# MSPM0G350X register map
Vendor: Texas Instruments; File version: This preliminary header file does not have a version number - build date: 2023-02-21 16:25:48
CPU: CM0 r0p1, little endian, MPU, no FPU, 3 interrupt priority bits
Registers are 32-bit, read-write, reset 0x0 unless marked. A register's access mark holds for its fields unless they carry their own. Offsets are from the block's base; [hi:lo] are bit positions; {n}, {i} and the like mark numbered series.

## COMP0 — PERIPHERALREGION
Base 0x40008000
Same registers: COMP1 0x4000A000, COMP2 0x4000C000
0x400 FSUB_0 — Subscriber Port 0
  [3:0] FSUB_0_CHANID — 0 = disconnected. 1-15 = connected to channelID = CHANID.
    0=FSUB_0_CHANID_UNCONNECTED (UNCONNECTED)
0x404 FSUB_1 — Subscriber Port 1
  [3:0] FSUB_1_CHANID — 0 = disconnected. 1-15 = connected to channelID = CHANID.
    0=FSUB_1_CHANID_UNCONNECTED (UNCONNECTED)
0x444 FPUB_1 — Publisher port 1
  [3:0] FPUB_1_CHANID — 0 = disconnected. 1-15 = connected to channelID = CHANID.
    0=FPUB_1_CHANID_UNCONNECTED (UNCONNECTED)
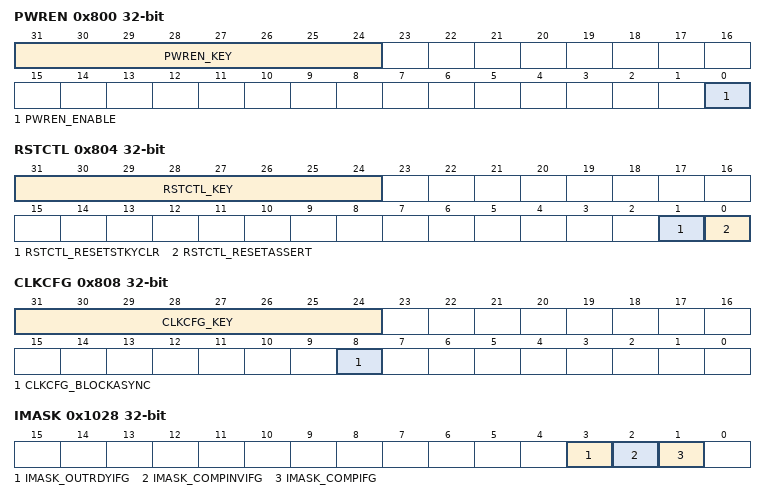
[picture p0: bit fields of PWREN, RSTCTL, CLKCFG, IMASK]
0x800 PWREN — Power enable
  [31:24] PWREN_KEY wo — KEY to allow Power State Change
    38=PWREN_KEY_UNLOCK_W (_TO_UNLOCK_W_)
  [0] PWREN_ENABLE — Enable the power
    0=PWREN_ENABLE_DISABLE (DISABLE); 1=PWREN_ENABLE_ENABLE (ENABLE)
0x804 RSTCTL wo — Reset Control
  [31:24] RSTCTL_KEY — Unlock key
    177=RSTCTL_KEY_UNLOCK_W (_TO_UNLOCK_W_)
  [1] RSTCTL_RESETSTKYCLR — Clear the RESETSTKY bit in the STAT register
    0=RSTCTL_RESETSTKYCLR_NOP (NOP); 1=RSTCTL_RESETSTKYCLR_CLR (CLR)
  [0] RSTCTL_RESETASSERT — Assert reset to the peripheral
    0=RSTCTL_RESETASSERT_NOP (NOP); 1=RSTCTL_RESETASSERT_ASSERT (ASSERT)
0x808 CLKCFG — Peripheral Clock Configuration Register
  [31:24] CLKCFG_KEY wo — KEY to Allow State Change -- 0xA9
    169=CLKCFG_KEY_UNLOCK (_UNLOCK_W_)
  [8] CLKCFG_BLOCKASYNC — Async Clock Request is blocked from starting SYSOSC or forcing bus clock to 32MHz
    0=CLKCFG_BLOCKASYNC_DISABLE (DISABLE); 1=CLKCFG_BLOCKASYNC_ENABLE (ENABLE)
0x814 GPRCM_STAT ro — Status Register
  [16] GPRCM_STAT_RESETSTKY — This bit indicates, if the peripheral was reset, since this bit was cleared by RESETSTKYCLR in the RSTCTL register
    0=GPRCM_STAT_RESETSTKY_NORES (NORES); 1=GPRCM_STAT_RESETSTKY_RESET (RESET)
0x1020 IIDX ro — Interrupt index
  [1:0] IIDX_STAT — Interrupt index status
    0=IIDX_STAT_NO_INTR (NO_INTR); 1=IIDX_STAT_OUTRDYIFG (OUTRDYIFG); 2=IIDX_STAT_COMPIFG (COMPIFG); 3=IIDX_STAT_COMPINVIFG (COMPINVIFG)
0x1028 IMASK — Interrupt mask
  [3] IMASK_OUTRDYIFG — Masks OUTRDYIFG
    0=IMASK_OUTRDYIFG_CLR (CLR); 1=IMASK_OUTRDYIFG_SET (SET)
  [2] IMASK_COMPINVIFG — Masks COMPINVIFG
    0=IMASK_COMPINVIFG_CLR (CLR); 1=IMASK_COMPINVIFG_SET (SET)
  [1] IMASK_COMPIFG — Masks COMPIFG
    0=IMASK_COMPIFG_CLR (CLR); 1=IMASK_COMPIFG_SET (SET)
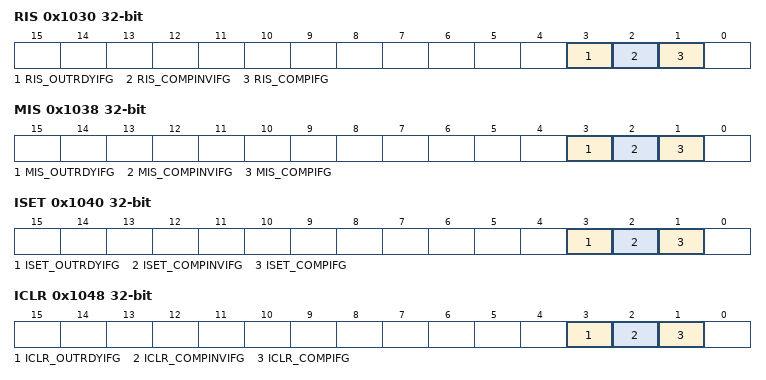
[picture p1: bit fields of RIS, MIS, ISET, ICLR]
0x1030 RIS ro — Raw interrupt status
  [3] RIS_OUTRDYIFG — Raw interrupt status for comparator output ready interrupt flag. This bit is set when the comparator output is valid.
    0=RIS_OUTRDYIFG_CLR (CLR); 1=RIS_OUTRDYIFG_SET (SET)
  [2] RIS_COMPINVIFG — Raw interrupt status for comparator output inverted interrupt flag. The IES bit defines the transition of the comparator output setting this bit.
    0=RIS_COMPINVIFG_CLR (CLR); 1=RIS_COMPINVIFG_SET (SET)
  [1] RIS_COMPIFG — Raw interrupt status for comparator output interrupt flag. The IES bit defines the transition of the comparator output setting this bit.
    0=RIS_COMPIFG_CLR (CLR); 1=RIS_COMPIFG_SET (SET)
0x1038 MIS ro — Masked interrupt status
  [3] MIS_OUTRDYIFG — Masked interrupt status for OUTRDYIFG
    0=MIS_OUTRDYIFG_CLR (CLR); 1=MIS_OUTRDYIFG_SET (SET)
  [2] MIS_COMPINVIFG — Masked interrupt status for COMPINVIFG
    0=MIS_COMPINVIFG_CLR (CLR); 1=MIS_COMPINVIFG_SET (SET)
  [1] MIS_COMPIFG — Masked interrupt status for COMPIFG
    0=MIS_COMPIFG_CLR (CLR); 1=MIS_COMPIFG_SET (SET)
0x1040 ISET wo — Interrupt set
  [3] ISET_OUTRDYIFG — Sets OUTRDYIFG in RIS register
    0=ISET_OUTRDYIFG_NO_EFFECT (NO_EFFECT); 1=ISET_OUTRDYIFG_SET (SET)
  [2] ISET_COMPINVIFG — Sets COMPINVIFG in RIS register
    0=ISET_COMPINVIFG_NO_EFFECT (NO_EFFECT); 1=ISET_COMPINVIFG_SET (SET)
  [1] ISET_COMPIFG — Sets COMPIFG in RIS register
    0=ISET_COMPIFG_NO_EFFECT (NO_EFFECT); 1=ISET_COMPIFG_SET (SET)
0x1048 ICLR wo — Interrupt clear
  [3] ICLR_OUTRDYIFG — Clears OUTRDYIFG in RIS register
    0=ICLR_OUTRDYIFG_NO_EFFECT (NO_EFFECT); 1=ICLR_OUTRDYIFG_CLR (CLR)
  [2] ICLR_COMPINVIFG — Clears COMPINVIFG in RIS register
    0=ICLR_COMPINVIFG_NO_EFFECT (NO_EFFECT); 1=ICLR_COMPINVIFG_CLR (CLR)
  [1] ICLR_COMPIFG — Clears COMPIFG in RIS register
    0=ICLR_COMPIFG_NO_EFFECT (NO_EFFECT); 1=ICLR_COMPIFG_CLR (CLR)
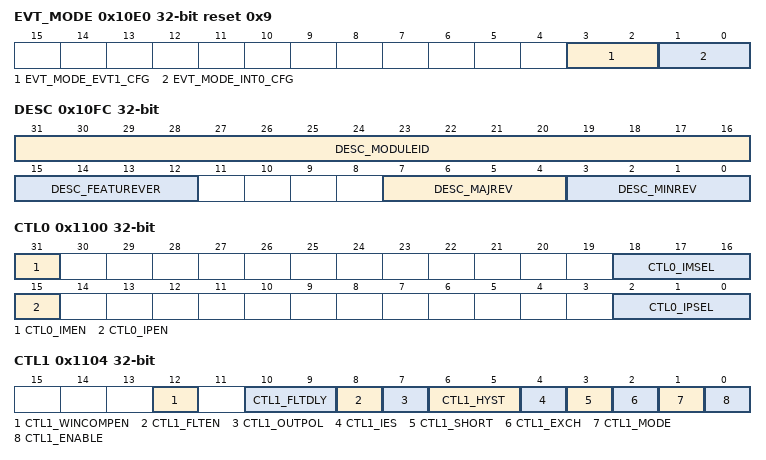
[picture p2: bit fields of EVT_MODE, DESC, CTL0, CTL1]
0x10E0 EVT_MODE reset 0x9 — Event Mode
  [3:2] EVT_MODE_EVT1_CFG ro — Event line mode select for event corresponding to [IPSTANDARD.INT_EVENT][0]
    0=EVT_MODE_EVT1_CFG_DISABLE (DISABLE); 1=EVT_MODE_EVT1_CFG_SOFTWARE (SOFTWARE); 2=EVT_MODE_EVT1_CFG_HARDWARE (HARDWARE)
  [1:0] EVT_MODE_INT0_CFG ro — Event line mode select for event corresponding to [IPSTANDARD.INT_EVENT][0]
    0=EVT_MODE_INT0_CFG_DISABLE (DISABLE); 1=EVT_MODE_INT0_CFG_SOFTWARE (SOFTWARE); 2=EVT_MODE_INT0_CFG_HARDWARE (HARDWARE)
0x10FC DESC ro — Module Description
  [31:16] DESC_MODULEID — Module identification contains a unique peripheral identification number. The assignments are maintained in a central database for all of the platform modules to ensure uniqueness.
  [15:12] DESC_FEATUREVER — Feature Set for the module *instance*
  [7:4] DESC_MAJREV — Major rev of the IP
  [3:0] DESC_MINREV — Minor rev of the IP
0x1100 CTL0 — Control 0
  [31] CTL0_IMEN — Channel input enable for the negative terminal of the comparator.
    0=CTL0_IMEN_DISABLE (DISABLE); 1=CTL0_IMEN_ENABLE (ENABLE)
  [18:16] CTL0_IMSEL — Channel input selected for the negative terminal of the comparator if IMEN is set to 1.
    {v}=CTL0_IMSEL_CH_{v} (CH_{v}) (v=0..7)
  [15] CTL0_IPEN — Channel input enable for the positive terminal of the comparator.
    0=CTL0_IPEN_DISABLE (DISABLE); 1=CTL0_IPEN_ENABLE (ENABLE)
  [2:0] CTL0_IPSEL — Channel input selected for the positive terminal of the comparator if IPEN is set to 1.
    {v}=CTL0_IPSEL_CH_{v} (CH_{v}) (v=0..7)
0x1104 CTL1 — Control 1
  [12] CTL1_WINCOMPEN — This bit enables window comparator operation of comparator.
    0=CTL1_WINCOMPEN_OFF (OFF); 1=CTL1_WINCOMPEN_ON (ON)
  [10:9] CTL1_FLTDLY — These bits select the comparator output filter delay. See the device-specific data sheet for specific values on comparator propagation delay for different filter delay settings.
    {v}=CTL1_FLTDLY_DLY_{v} (DLY_{v}) (v=0..3)
  [8] CTL1_FLTEN — This bit enables the analog filter at comparator output.
    0=CTL1_FLTEN_DISABLE (DISABLE); 1=CTL1_FLTEN_ENABLE (ENABLE)
  [7] CTL1_OUTPOL — This bit selects the comparator output polarity.
    0=CTL1_OUTPOL_NON_INV (NON_INV); 1=CTL1_OUTPOL_INV (INV)
  [6:5] CTL1_HYST — These bits select the hysteresis setting of the comparator.
    0=CTL1_HYST_NO_HYS (NO_HYS); 1=CTL1_HYST_LOW_HYS (LOW_HYS); 2=CTL1_HYST_MED_HYS (MED_HYS); 3=CTL1_HYST_HIGH_HYS (HIGH_HYS)
  [4] CTL1_IES — This bit selected the interrupt edge for COMPIFG and COMPINVIFG.
    0=CTL1_IES_RISING (RISING); 1=CTL1_IES_FALLING (FALLING)
  [3] CTL1_SHORT — This bit shorts the positive and negative input terminals of the comparator.
    0=CTL1_SHORT_NO_SHT (NO_SHT); 1=CTL1_SHORT_SHT (SHT)
  [2] CTL1_EXCH — This bit exchanges the comparator inputs and inverts the comparator output.
    0=CTL1_EXCH_NO_EXC (NO_EXC); 1=CTL1_EXCH_EXC (EXC)
  [1] CTL1_MODE — This bit selects the comparator operating mode.
    0=CTL1_MODE_FAST (FAST); 1=CTL1_MODE_ULP (ULP)
  [0] CTL1_ENABLE — This bit turns on the comparator. When the comparator is turned off it consumes no power.
    0=CTL1_ENABLE_OFF (OFF); 1=CTL1_ENABLE_ON (ON)
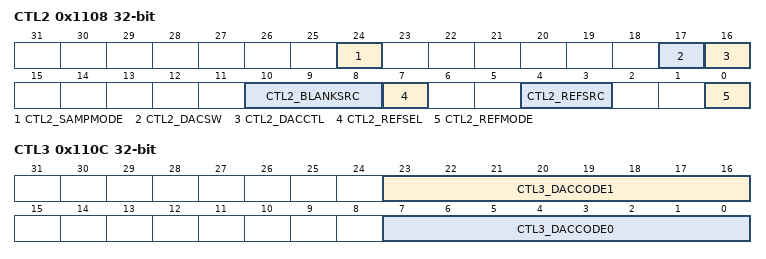
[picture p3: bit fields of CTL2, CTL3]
0x1108 CTL2 — Control 2
  [24] CTL2_SAMPMODE — Enable sampled mode of comparator.
    0=CTL2_SAMPMODE_DISABLE (DISABLE); 1=CTL2_SAMPMODE_ENABLE (ENABLE)
  [17] CTL2_DACSW — This bit selects between DACCODE0 and DACCODE1 to 8-bit DAC when DACCTL bit is 1.
    0=CTL2_DACSW_DACCODE0_SEL (DACCODE0_SEL); 1=CTL2_DACSW_DACCODE1_SEL (DACCODE1_SEL)
  [16] CTL2_DACCTL — This bit determines if the comparator output or DACSW bit controls the selection between DACCODE0 and DACCODE1.
    0=CTL2_DACCTL_COMPOUT_SEL (COMPOUT_SEL); 1=CTL2_DACCTL_DACSW_SEL (DACSW_SEL)
  [10:8] CTL2_BLANKSRC — These bits select the blanking source for the comparator.
    0=CTL2_BLANKSRC_DISABLE (DISABLE); {v}=CTL2_BLANKSRC_BLANKSRC{v} (BLANKSRC{v}) (v=1..6)
  [7] CTL2_REFSEL — This bit selects if the selected reference voltage is applied to positive or negative terminal of the comparator.
    0=CTL2_REFSEL_POSITIVE (POSITIVE); 1=CTL2_REFSEL_NEGATIVE (NEGATIVE)
  [4:3] CTL2_REFSRC — These bits select the reference source for the comparator.
    0=CTL2_REFSRC_OFF (OFF); 1=CTL2_REFSRC_VDDA_DAC (VDDA_DAC); 2=CTL2_REFSRC_VREF_DAC (VREF_DAC); 3=CTL2_REFSRC_VREF (VREF)
  [0] CTL2_REFMODE — This bit requests ULP_REF bandgap operation in static mode or sampled mode. The local reference buffer and 8-bit DAC inside comparator module are also configured accordingly. Static mode operation offers higher accuracy but consumes higher current. Sampled mode operation consumes lower current but with relaxed reference voltage accuracy. Comparator requests for reference voltage from ULP_REF only when REFLVL > 0.
    0=CTL2_REFMODE_STATIC (STATIC); 1=CTL2_REFMODE_SAMPLED (SAMPLED)
0x110C CTL3 — Control 3
  [23:16] CTL3_DACCODE1 — This is the second 8-bit DAC code. When the DAC code is 0x0 the DAC output will be 0 V. When the DAC code is 0xFF the DAC output will be selected reference voltage x 255/256.
  [7:0] CTL3_DACCODE0 — This is the first 8-bit DAC code. When the DAC code is 0x0 the DAC output will be 0 V. When the DAC code is 0xFF the DAC output will be selected reference voltage x 255/256.
0x1120 STAT ro — Status
  [0] STAT_OUT — This bit reflects the value of the comparator output. Writing to this bit has no effect on the comparator output.
    0=STAT_OUT_LOW (LOW); 1=STAT_OUT_HIGH (HIGH)

## WUC — PERIPHERALREGION
Base 0x40424000
Registers as COMP0, without FPUB_1, PWREN, RSTCTL, CLKCFG, GPRCM_STAT, IIDX, IMASK, RIS, MIS, ISET, ICLR, EVT_MODE, DESC, CTL{n} (n=0..3), STAT.
